# G32R501 register map
Vendor: Geehy Semiconductor Co., Ltd.; Series: G32R5; File version: 1.0
CPU: CM55 r0p1, little endian, MPU, FPU, double-precision FPU, DSP, VTOR, 4 interrupt priority bits
Registers are 32-bit, read-write, reset 0x0 unless marked. A register's access mark holds for its fields unless they carry their own. Offsets are from the block's base; [hi:lo] are bit positions; {n}, {i} and the like mark numbered series.

## CPU — CPU_REGS
Base 0x50020A00
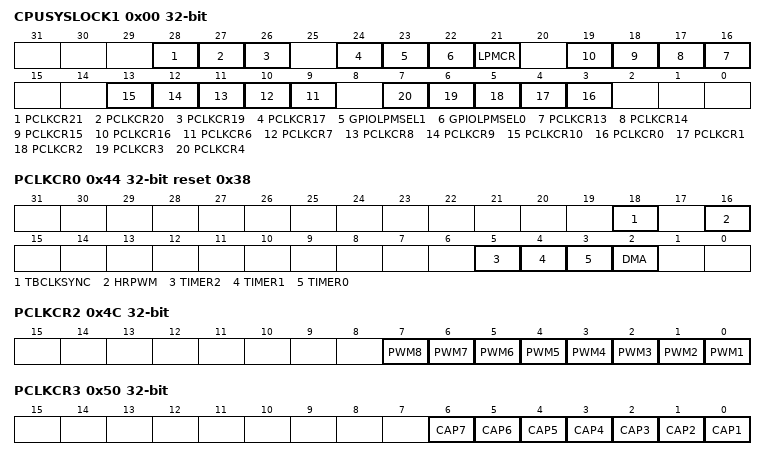
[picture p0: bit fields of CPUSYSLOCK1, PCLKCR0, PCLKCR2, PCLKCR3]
0x00 CPUSYSLOCK1 — Lock bit for CPUSYS registers
  [28] PCLKCR21 — Lock bit for PCLKCR21 Register
  [27] PCLKCR20 — Lock bit for PCLKCR20 Register
  [26] PCLKCR19 — Lock bit for PCLKCR19 Register
  [24] PCLKCR17 — Lock bit for PCLKCR17 Register
  [23] GPIOLPMSEL1 — Lock bit for GPIOLPMSEL1 Register
  [22] GPIOLPMSEL0 — Lock bit for GPIOLPMSEL0 Register
  [21] LPMCR — Lock bit for LPMCR Register
  [n+3] PCLKCR{n} (n=13..16) — Lock bit for PCLKCR{n} Register
  [n+3] PCLKCR{n} (n=6..10) — Lock bit for PCLKCR{n} Register
  [n+3] PCLKCR{n} (n=0..4) — Lock bit for PCLKCR{n} Register
0x44 PCLKCR0 reset 0x38 — Peripheral Clock Gating Registers
  [18] TBCLKSYNC — PWM Time Base Clock sync
  [16] HRPWM — HRPWM Clock Enable Bit
  [5] TIMER2 — TIMER2 Clock Enable bit
  [4] TIMER1 — TIMER1 Clock Enable bit
  [3] TIMER0 — TIMER0 Clock Enable bit
  [2] DMA — DMA Clock Enable bit
0x48 PCLKCR1 — Peripheral Clock Gating Registers
  [0] QSPICLKEN — QSPI Clock Enable bit
0x4C PCLKCR2 — Peripheral Clock Gating Registers
  [n-1] PWM{n} (n=1..8) — PWM{n} Clock Enable bit
0x50 PCLKCR3 — Peripheral Clock Gating Registers
  [n-1] CAP{n} (n=1..7) — CAP{n} Clock Enable bit
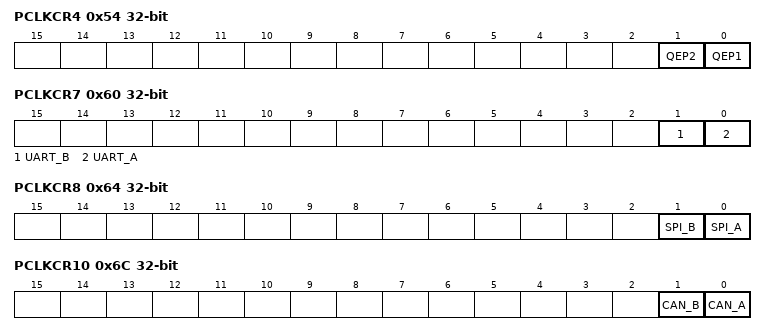
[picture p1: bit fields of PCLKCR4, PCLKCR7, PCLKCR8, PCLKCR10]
0x54 PCLKCR4 — Peripheral Clock Gating Registers
  [1] QEP2 — QEP2 Clock Enable bit
  [0] QEP1 — QEP1 Clock Enable bit
0x5C PCLKCR6 — Peripheral Clock Gating Registers
  [0] SD1 — SD1 Clock Enable bit
0x60 PCLKCR7 — Peripheral Clock Gating Registers
  [1] UART_B — UART_B Clock Enable bit
  [0] UART_A — UART_A Clock Enable bit
0x64 PCLKCR8 — Peripheral Clock Gating Registers
  [1] SPI_B — SPI_B Clock Enable bit
  [0] SPI_A — SPI_A Clock Enable bit
0x68 PCLKCR9 — Peripheral Clock Gating Registers
  [0] I2C_A — I2C_A Clock Enable bit
0x6C PCLKCR10 — Peripheral Clock Gating Registers
  [1] CAN_B — CAN_B Clock Enable bit
  [0] CAN_A — CAN_A Clock Enable bit
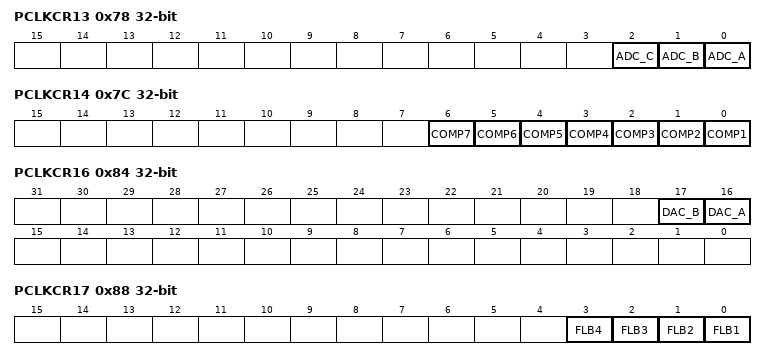
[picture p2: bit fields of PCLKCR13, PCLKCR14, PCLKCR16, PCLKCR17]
0x78 PCLKCR13 — Peripheral Clock Gating Registers
  [2] ADC_C — ADC_C Clock Enable bit
  [1] ADC_B — ADC_B Clock Enable bit
  [0] ADC_A — ADC_A Clock Enable bit
0x7C PCLKCR14 — Peripheral Clock Gating Registers
  [n-1] COMP{n} (n=1..7) — COMP{n}CLKEN Clock Enable bit
0x84 PCLKCR16 — Peripheral Clock Gating Registers
  [17] DAC_B — DAC_B Clock Enable bit
  [16] DAC_A — DAC_A Clock Enable bit
0x88 PCLKCR17 — Peripheral Clock Gating Registers
  [n-1] FLB{n} (n=1..4) — FLB{n} Clock Enable bit
0x90 PCLKCR19 — Peripheral Clock Gating Registers
  [0] LIN_A — LIN_A Clock Enable bit
0x94 PCLKCR20 — Peripheral Clock Gating Registers
  [0] PMBUS_A — PMBUS_A Clock Enable bit
0x98 PCLKCR21 — Peripheral Clock Gating Registers
  [0] DCC_0 — DCC_0 Clock Enable bit
0xEC LPMCR reset 0xFC — LPM Control Register
  [1:0] LPM — These bits set the low power mode for the device
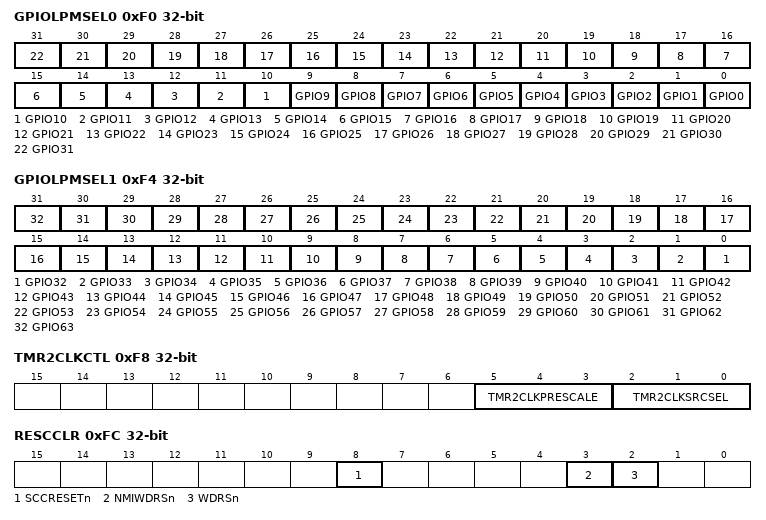
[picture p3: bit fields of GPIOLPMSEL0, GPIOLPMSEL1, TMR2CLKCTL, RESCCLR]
0xF0 GPIOLPMSEL0 — GPIO LPM Wakeup select registers
  [n] GPIO{n} (n=0..31) — Pin is connected/disconnected from LPM circuit
0xF4 GPIOLPMSEL1 — GPIO LPM Wakeup select registers
  [n-32] GPIO{n} (n=32..63) — Pin is connected/disconnected from LPM circuit
0xF8 TMR2CLKCTL — Timer2 Clock Measurement functionality control register
  [5:3] TMR2CLKPRESCALE — Timer 2 Clock Pre-Scale Value
  [2:0] TMR2CLKSRCSEL — Timer 2 Clock Source Select Bit
0xFC RESCCLR wo — Reset Cause Clear Register
  [8] SCCRESETn — Clear bit for corresponding status bit in RESC
  [3] NMIWDRSn — Clear bit for corresponding status bit in RESC
  [2] WDRSn — Clear bit for corresponding status bit in RESC
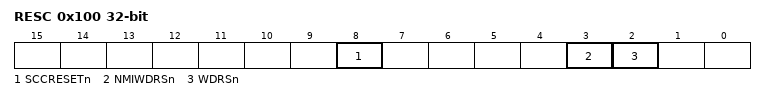
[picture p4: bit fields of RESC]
0x100 RESC ro — Reset Cause register
  [8] SCCRESETn — If this bit is set, indicates that the device was reset by SCCRESETn (fired by DCS)
  [3] NMIWDRSn — If this bit is set, indicates that the device was reset by NMIWDRSn
  [2] WDRSn — If this bit is set, indicates that the device was reset by WDRSn
